# CTRL_MODULE_CORE register map
Vendor: Texas Instruments
Registers are 32-bit, access per field, reset 0x0 unless marked. A register's access mark holds for its fields unless they carry their own. Offsets are as the file gives them; [hi:lo] are bit positions; {n}, {i} and the like mark numbered series.

## CTRL_MODULE_CORE (part 2 of 12)
0x134 CTRL_CORE_STATUS ro reset 0xC0 — Control Module Status Register
  [8:6] DEVICE_TYPE — Device type captured at reset time. Read 0x3 = General Purpose (GP)
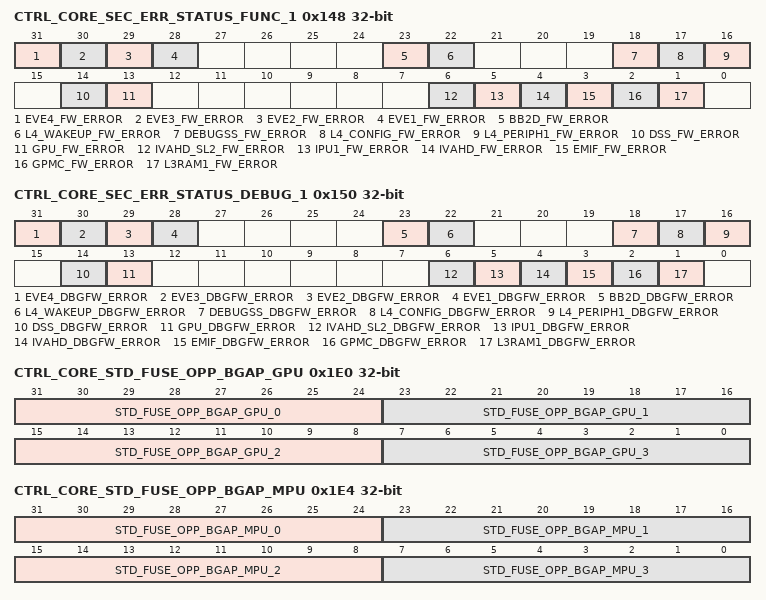
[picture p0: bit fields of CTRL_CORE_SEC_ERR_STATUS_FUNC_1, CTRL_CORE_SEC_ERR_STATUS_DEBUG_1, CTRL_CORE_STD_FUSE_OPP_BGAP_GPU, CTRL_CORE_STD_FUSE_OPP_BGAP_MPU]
0x148 CTRL_CORE_SEC_ERR_STATUS_FUNC_1 access not given — Firewall Error Status functional Register 1
  [31] EVE4_FW_ERROR — EVE4 firewall 0x0: No error firewall 0x1: Error from firewall (access RW W1toClr)
  [30] EVE3_FW_ERROR — EVE3 firewall 0x0: No error firewall 0x1: Error from firewall (access RW W1toClr)
  [29] EVE2_FW_ERROR — EVE2 firewall 0x0 = No error from firewall 0x1 = Error from firewall (access RW W1toClr)
  [28] EVE1_FW_ERROR — EVE1 firewall 0x0 = No error from firewall 0x1 = Error from firewall (access RW W1toClr)
  [23] BB2D_FW_ERROR — BB2D firewall 0x0 = No error from firewall 0x1 = Error from firewall (access RW W1toClr)
  [22] L4_WAKEUP_FW_ERROR — L4 wakeup firewall 0x0 = No error from firewall 0x1 = Error from firewall (access RW W1toClr)
  [18] DEBUGSS_FW_ERROR — DebugSS firewall 0x0 = No error from firewall 0x1 = Error from firewall (access RW W1toClr)
  [17] L4_CONFIG_FW_ERROR — L4 config firewall 0x0 = No error from firewall 0x1 = Error from firewall (access RW W1toClr)
  [16] L4_PERIPH1_FW_ERROR — L4 periph1 firewall 0x0 = No error from firewall 0x1 = Error from firewall (access RW W1toClr)
  [14] DSS_FW_ERROR — DSS firewall 0x0 = No error from firewall 0x1 = Error from firewall (access RW W1toClr)
  [13] GPU_FW_ERROR — GPU firewall 0x0 = No error from firewall 0x1 = Error from firewall (access RW W1toClr)
  [6] IVAHD_SL2_FW_ERROR — IVAHD SL2 firewall 0x0 = No error from firewall 0x1 = Error from firewall (access RW W1toClr)
  [5] IPU1_FW_ERROR — IPU1 firewall 0x0 = No error from firewall 0x1 = Error from firewall (access RW W1toClr)
  [4] IVAHD_FW_ERROR — IVAHD firewall 0x0 = No error from firewall 0x1 = Error from firewall (access RW W1toClr)
  [3] EMIF_FW_ERROR — EMIF firewall 0x0 = No error from firewall 0x1 = Error from firewall (access RW W1toClr)
  [2] GPMC_FW_ERROR — GPMC firewall 0x0 = No error from firewall 0x1 = Error from firewall (access RW W1toClr)
  [1] L3RAM1_FW_ERROR — L3RAM1 firewall 0x0 = No error from firewall 0x1 = Error from firewall (access RW W1toClr)
0x150 CTRL_CORE_SEC_ERR_STATUS_DEBUG_1 access not given — Firewall Error Status Debug Register 1
  [31] EVE4_DBGFW_ERROR — EVE4 firewall 0x0: No error firewall 0x1: Error from firewall (access RW W1toClr)
  [30] EVE3_DBGFW_ERROR — EVE3 firewall 0x0: No error firewall 0x1: Error from firewall (access RW W1toClr)
  [29] EVE2_DBGFW_ERROR — EVE2 firewall 0x0 = No error from firewall 0x1 = Error from firewall (access RW W1toClr)
  [28] EVE1_DBGFW_ERROR — EVE1 firewall 0x0 = No error from firewall 0x1 = Error from firewall (access RW W1toClr)
  [23] BB2D_DBGFW_ERROR — BB2D firewall 0x0 = No error from firewall 0x1 = Error from firewall (access RW W1toClr)
  [22] L4_WAKEUP_DBGFW_ERROR — L4 wakeup firewall 0x0 = No error from firewall 0x1 = Error from firewall (access RW W1toClr)
  [18] DEBUGSS_DBGFW_ERROR — DebugSS firewall 0x0 = No error from firewall 0x1 = Error from firewall (access RW W1toClr)
  [17] L4_CONFIG_DBGFW_ERROR — L4 config firewall 0x0 = No error from firewall 0x1 = Error from firewall (access RW W1toClr)
  [16] L4_PERIPH1_DBGFW_ERROR — L4 periph1 firewall 0x0 = No error from firewall 0x1 = Error from firewall (access RW W1toClr)
  [14] DSS_DBGFW_ERROR — DSS debug firewall 0x0 = No error from firewall 0x1 = Error from firewall (access RW W1toClr)
  [13] GPU_DBGFW_ERROR — GPU debug firewall 0x0 = No error from firewall 0x1 = Error from firewall (access RW W1toClr)
  [6] IVAHD_SL2_DBGFW_ERROR — IVAHD SL2 debug firewall 0x0 = No error from firewall 0x1 = Error from firewall (access RW W1toClr)
  [5] IPU1_DBGFW_ERROR — IPU1 debug firewall 0x0 = No error from firewall 0x1 = Error from firewall (access RW W1toClr)
  [4] IVAHD_DBGFW_ERROR — IVAHD debug firewall 0x0 = No error from firewall 0x1 = Error from firewall (access RW W1toClr)
  [3] EMIF_DBGFW_ERROR — EMIF debug firewall 0x0 = No error from firewall 0x1 = Error from firewall (access RW W1toClr)
  [2] GPMC_DBGFW_ERROR — GPMC debug firewall 0x0 = No error from firewall 0x1 = Error from firewall (access RW W1toClr)
  [1] L3RAM1_DBGFW_ERROR — L3RAM1 debug firewall 0x0 = No error from firewall 0x1 = Error from firewall (access RW W1toClr)
0x15C CTRL_CORE_MPU_FORCEWRNP — FORCE WRITE NON POSTED
  [0] MPU_FORCEWRNP rw — Force mpu write non posted transactions 0x0 = disable force wrnp 0x1 = force wrnp
{0x194+4i} CTRL_CORE_STD_FUSE_OPP_VDD_GPU_{i} ro (i=0..5) — Standard Fuse OPP VDD_GPU [{32i+31}:{32i}]. Register shows part of the chip eFuse configuration on the OCP interface. Reading at the address of one of these registers provides a direct view into a part of the eFuse chain.
  [31:0] STD_FUSE_OPP_VDD_GPU_{i}
{0x1AC+4i} CTRL_CORE_STD_FUSE_OPP_VDD_MPU_{i} ro (i=0..7) — Standard Fuse OPP VDD_MPU [{32i+31}:{32i}]. Register shows part of the chip eFuse configuration on the OCP interface. Reading at the address of one of these registers provides a direct view into a part of the eFuse chain.
  [31:0] STD_FUSE_OPP_VDD_MPU_{i}
{0x1CC+4i} CTRL_CORE_STD_FUSE_OPP_VDD_CORE_{i} ro (i=0..4) — Standard Fuse OPP VDD_CORE [{32i+31}:{32i}]. Register shows part of the chip eFuse configuration on the OCP interface. Reading at the address of one of these registers provides a direct view into a part of the eFuse chain.
  [31:0] STD_FUSE_OPP_VDD_CORE_{i}
0x1E0 CTRL_CORE_STD_FUSE_OPP_BGAP_GPU ro reset not defined — Trim values for GPU associated temperature sensor and bandgap. Contains TI Internal information, not intended for application use.
  [31-8n:24-8n] STD_FUSE_OPP_BGAP_GPU_{n} (n=0..3) — Trim values for GPU associated temperature sensor and bandgap. Contains TI Internal information, not intended for application use.
0x1E4 CTRL_CORE_STD_FUSE_OPP_BGAP_MPU ro reset not defined — Trim values for MPU associated temperature sensor and bandgap. Contains TI Internal information, not intended for application use.
  [31-8n:24-8n] STD_FUSE_OPP_BGAP_MPU_{n} (n=0..3) — Trim values for MPU associated temperature sensor and bandgap. Contains TI Internal information, not intended for application use.
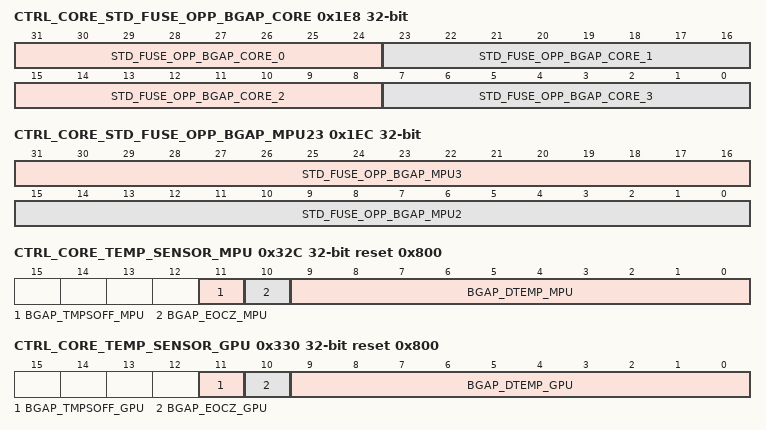
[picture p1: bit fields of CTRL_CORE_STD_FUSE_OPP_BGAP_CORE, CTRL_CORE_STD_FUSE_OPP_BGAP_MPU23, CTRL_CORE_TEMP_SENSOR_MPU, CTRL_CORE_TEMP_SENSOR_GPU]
0x1E8 CTRL_CORE_STD_FUSE_OPP_BGAP_CORE ro reset not defined — Trim values for CORE associated temperature sensor and bandgap. Contains TI Internal information, not intended for application use.
  [31-8n:24-8n] STD_FUSE_OPP_BGAP_CORE_{n} (n=0..3) — Trim values for CORE associated temperature sensor and bandgap. Contains TI Internal information, not intended for application use.
0x1EC CTRL_CORE_STD_FUSE_OPP_BGAP_MPU23 ro — Standard Fuse OPP BGAP. Register shows part of the chip eFuse configuration on the OCP interface. Reading at the address of one of these registers provides a direct view into a part of the eFuse chain.
  [31:16] STD_FUSE_OPP_BGAP_MPU3, [15:0] STD_FUSE_OPP_BGAP_MPU2
{0x220+4i} CTRL_CORE_STD_FUSE_MPK_{i} ro (i=0..7) — Standard Fuse keys. Root_public_key_hash [{32i+31}:{32i}]. Register shows part of the chip eFuse configuration on the OCP interface. Reading at the address of one of these registers provides a direct view into a part of the eFuse chain.
  [31:0] STD_FUSE_MPK_{i}
{0x240+4i} CTRL_CORE_STD_FUSE_OPP_VDD_GPU_LVT_{i} ro (i=0..5) — Standard Fuse OPP VDD_GPU [{32i+31}:{32i}]. Register shows part of the chip eFuse configuration on the OCP interface. Reading at the address of one of these registers provides a direct view into a part of the eFuse chain.
  [31:0] STD_FUSE_OPP_VDD_GPU_LVT_{i}
{0x258+4i} CTRL_CORE_STD_FUSE_OPP_VDD_MPU_LVT_{i} ro (i=0..7) — Standard Fuse OPP VDD_MPU [{32i+31}:{32i}]. Register shows part of the chip eFuse configuration on the OCP interface. Reading at the address of one of these registers provides a direct view into a part of the eFuse chain.
  [31:0] STD_FUSE_OPP_VDD_MPU_LVT_{i}
0x2BC CTRL_CORE_CUST_FUSE_SWRV_0 ro — Customer Fuse keys. Software Version Control [031:000] (16 bits upper Redundant field) [FIELD OVERFLOW]. Register shows part of the chip eFuse configuration on the OCP interface. Reading at the address of one of these registers provides a direct view into a part of the eFuse chain.
  [31:0] CUST_FUSE_SWRV_0
0x2C0 CTRL_CORE_CUST_FUSE_SWRV_1 ro — Customer Fuse keys. Software Version Control [063:032] (16 bits upper Redundant field) [FIELD F]. Register shows part of the chip eFuse configuration on the OCP interface. Reading at the address of one of these registers provides a direct view into a part of the eFuse chain.
  [31:0] CUST_FUSE_SWRV_1
0x2C4 CTRL_CORE_CUST_FUSE_SWRV_2 ro — Customer Fuse keys. Software Version Control [095:064] (16 bits upper Redundant field) [FIELD E]. Register shows part of the chip eFuse configuration on the OCP interface. Reading at the address of one of these registers provides a direct view into a part of the eFuse chain.
  [31:0] CUST_FUSE_SWRV_2
0x2C8 CTRL_CORE_CUST_FUSE_SWRV_3 ro — Customer Fuse keys. Software Version Control [127:096] (16 bits upper Redundant field) [FIELD D]. Register shows part of the chip eFuse configuration on the OCP interface. Reading at the address of one of these registers provides a direct view into a part of the eFuse chain.
  [31:0] CUST_FUSE_SWRV_3
0x2CC CTRL_CORE_CUST_FUSE_SWRV_4 ro — Customer Fuse keys. Software Version Control [159:127] (16 bits upper Redundant field) [FIELD C]. Register shows part of the chip eFuse configuration on the OCP interface. Reading at the address of one of these registers provides a direct view into a part of the eFuse chain.
  [31:0] CUST_FUSE_SWRV_4
0x2D0 CTRL_CORE_CUST_FUSE_SWRV_5 ro — Customer Fuse keys. Software Version Control [191:160] (16 bits upper Redundant field) [FIELD B]. Register shows part of the chip eFuse configuration on the OCP interface. Reading at the address of one of these registers provides a direct view into a part of the eFuse chain.
  [31:0] CUST_FUSE_SWRV_5
0x2D4 CTRL_CORE_CUST_FUSE_SWRV_6 ro — Customer Fuse keys. Software Version Control [223:192] (16 bits upper Redundant field) [FIELD A]. Register shows part of the chip eFuse configuration on the OCP interface. Reading at the address of one of these registers provides a direct view into a part of the eFuse chain.
  [31:0] CUST_FUSE_SWRV_6
0x300 CTRL_CORE_DEV_CONF ro — This register is used to power down the USB2_PHY1
  [0] USBPHY_PD — Power down the entire USB2_PHY1 (data, common module and UTMI). 0x0: Normal operation 0x1: Power down the USB2_PHY1
0x32C CTRL_CORE_TEMP_SENSOR_MPU ro reset 0x800 — Control VBGAPTS temperature sensor and thermal comparator shutdown register
  [11] BGAP_TMPSOFF_MPU — This bit indicates the temperature sensor state.
  [10] BGAP_EOCZ_MPU — ADC End of Conversion. Active low, when BGAP_DTEMP_MPU is valid.
  [9:0] BGAP_DTEMP_MPU — Temperature data from the ADC. Valid if EOCZ is low.
0x330 CTRL_CORE_TEMP_SENSOR_GPU ro reset 0x800 — Control VBGAPTS temperature sensor and thermal comparator shutdown register
  [11] BGAP_TMPSOFF_GPU — This bit indicates the temperature sensor state.
  [10] BGAP_EOCZ_GPU — ADC End of Conversion. Active low, when BGAP_DTEMP_GPU is valid.
  [9:0] BGAP_DTEMP_GPU — Temperature data from the ADC. Valid if EOCZ is low.
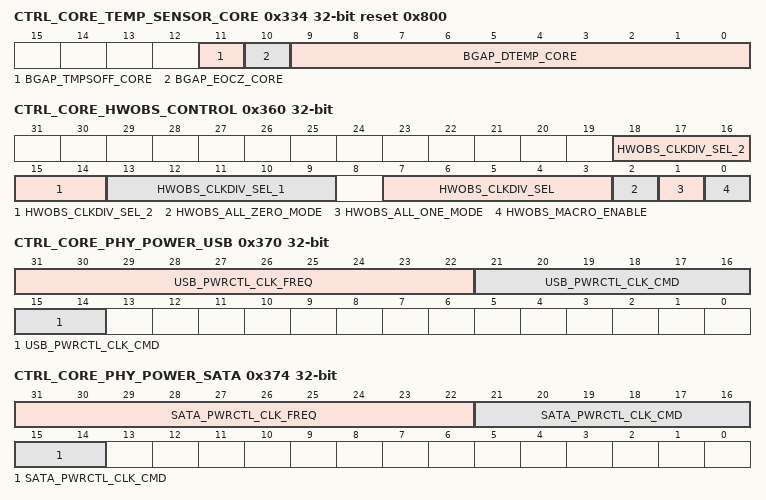
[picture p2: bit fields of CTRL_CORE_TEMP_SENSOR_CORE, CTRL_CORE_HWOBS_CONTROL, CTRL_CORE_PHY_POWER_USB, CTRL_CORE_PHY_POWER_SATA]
0x334 CTRL_CORE_TEMP_SENSOR_CORE ro reset 0x800 — Control VBGAPTS temperature sensor and thermal comparator shutdown register
  [11] BGAP_TMPSOFF_CORE — This bit indicates the temperature sensor state.
  [10] BGAP_EOCZ_CORE — ADC End of Conversion. Active low, when BGAP_DTEMP_CORE is valid.
  [9:0] BGAP_DTEMP_CORE — Temperature data from the ADC. Valid if EOCZ is low.
0x358 CTRL_CORE_CORTEX_M4_MMUADDRTRANSLTR — Cortex M4 register
  [19:0] CORTEX_M4_MMUADDRTRANSLTR rw — Used to save the mmu address boot
0x35C CTRL_CORE_CORTEX_M4_MMUADDRLOGICTR
  [19:0] CORTEX_M4_MMUADDRLOGICTR rw
0x360 CTRL_CORE_HWOBS_CONTROL — HW observability control. This register enables or disables HW observability outputs (to save power primarily)
  [18:14] HWOBS_CLKDIV_SEL_2 rw — Clock divider selection on po_hwobs(2). 0x1 = output is not divided 0x2 = output is divided by 2 0x4 = output is divided by 4 0x8 = output is divided by 8 0x10 = output is divided by 16
  [13:9] HWOBS_CLKDIV_SEL_1 rw — Clock divider selection on po_hwobs(1). 0x1 = output is not divided 0x2 = output is divided by 2 0x4 = output is divided by 4 0x8 = output is divided by 8 0x10 = output is divided by 16
  [7:3] HWOBS_CLKDIV_SEL rw — Clock divider selection on po_hwobs(0). 0x1 = output is not divided 0x2 = output is divided by 2 0x4 = output is divided by 4 0x8 = output is divided by 8 0x10 = output is divided by 16
  [2] HWOBS_ALL_ZERO_MODE rw — Used to gate observable signals. When set all outputs are set to zero (can be used to check the path from HW observability to external pads). 0x0 = hw observability ports are not gated 0x1 = hw observability ports are all set to 0
  [1] HWOBS_ALL_ONE_MODE rw — Used to gate observable signals. When set all outputs are set to one (can be used to check the path from HW observability to external pads). 0x0 = hw observability ports are not gated 0x1 = hw observability ports are all set to 1
  [0] HWOBS_MACRO_ENABLE rw — Used to gate observable signals coming from macros using the 32:bit HWOBS bus definition. When deasserted all outputs of the HWOBS busdef are set to zero. 0x0 = hw observability ports from macros are gated and set to zero 0x1 = hw observability ports from macros are not gated
0x370 CTRL_CORE_PHY_POWER_USB — phy_power_usb
  [31:22] USB_PWRCTL_CLK_FREQ rw — Frequency of SYSCLK1 in MHz (rounded). For example, for 20MHz, program 0x14.
  [21:14] USB_PWRCTL_CLK_CMD rw — Powers up/down the USB3_PHY_TX and USB3_PHY_RX modules. This bit field is also used for partially power down these TX and RX modules. Each bit has the following meaning: Bit[14] - 0x1: Powers-up the USB3_PHY_RX Bit[15] - 0x1: Powers-up the USB3_PHY_TX Bit[16] - A don’t care bit. Not used. Bit[17] - A don’t care bit. Not used. Bit[18] - 0x1: Disables the synchronized power-up of USB3_PHY_TX with USB3_PHY_RX. The TX power-up is independent of the RX power-up. Bit[19] - 0x1: Disables the automatic power-cycling of USB3_PHY_RX in P3 power state when PLL_CLK stops and starts. Bit[20] - 0x1: Partially powers-down the USB3_PHY_RX when it is in P3 power state. DCC, Phase interpolator, Equalizer are disabled. Bit[21] - A don’t care bit. Not used.
0x374 CTRL_CORE_PHY_POWER_SATA — phy_power_sata
  [31:22] SATA_PWRCTL_CLK_FREQ rw — Frequency of SYSCLK1 in MHz (rounded). For example, for 20MHz, program 0x14.
  [21:14] SATA_PWRCTL_CLK_CMD rw — Powers up/down the SATA_PHY_TX and SATA_PHY_RX modules. 0x0: Powers down SATA_PHY_TX and SATA_PHY_RX 0x1: Powers up SATA_PHY_RX 0x2: Powers up SATA_PHY_TX 0x3: Powers up SATA_PHY_TX and SATA_PHY_RX 0x4-0xFF: Reserved
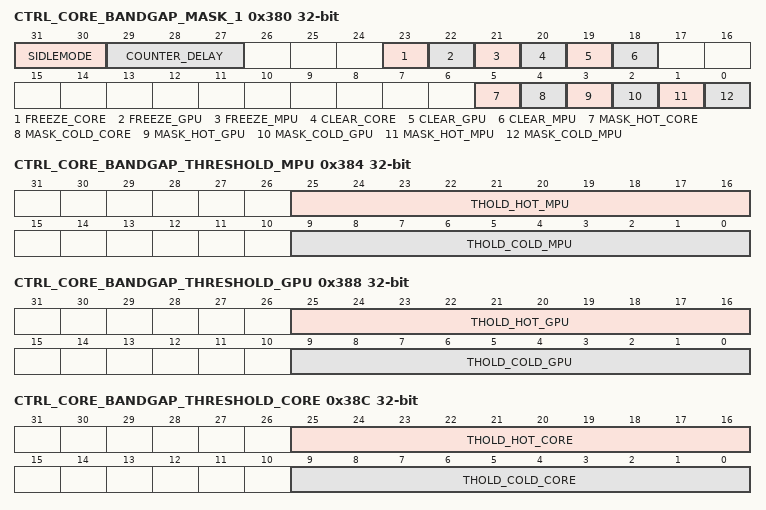
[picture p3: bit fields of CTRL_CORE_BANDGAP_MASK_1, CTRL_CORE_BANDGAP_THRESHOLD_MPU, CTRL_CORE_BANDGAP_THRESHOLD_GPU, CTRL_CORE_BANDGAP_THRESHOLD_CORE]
0x380 CTRL_CORE_BANDGAP_MASK_1 — bgap_mask
  [31:30] SIDLEMODE rw — sidlemode for bandgap 0x0 = No Idle 0x1 = Force Idle 0x2 = Smart Idle 0x3 = Reserved
  [29:27] COUNTER_DELAY rw — Counter delay 0x0 = Imediat 0x1 = Delay of 1ms 0x2 = Delay of 10ms 0x3 = Delay of 100ms 0x4 = Delay of 250ms 0x5 = Delay of 500ms
  [23] FREEZE_CORE rw — Freeze the FIFO CORE 0x0 = No operation 0x1 = Freeze the FIFO
  [22] FREEZE_GPU rw — Freeze the FIFO GPU 0x0 = No operation 0x1 = Freeze the FIFO
  [21] FREEZE_MPU rw — Freeze the FIFO MPU 0x0 = No operation 0x1 = Freeze the FIFO
  [20] CLEAR_CORE rw — Reset the FIFO CORE 0x0 = No operation 0x1 = Reset the FIFO
  [19] CLEAR_GPU rw — Reset the FIFO GPU 0x0 = No operation 0x1 = Reset the FIFO
  [18] CLEAR_MPU rw — Reset the FIFO MPU 0x0 = No operation 0x1 = Reset the FIFO
  [5] MASK_HOT_CORE rw — Mask for hot event CORE 0x0 = hot event is masked 0x1 = hot event is not masked
  [4] MASK_COLD_CORE rw — Mask for cold event CORE 0x0 = cold event is masked 0x1 = cold event is not masked
  [3] MASK_HOT_GPU rw — Mask for hot event GPU 0x0 = hot event is masked 0x1 = hot event is not masked
  [2] MASK_COLD_GPU rw — Mask for cold event GPU 0x0 = cold event is masked 0x1 = cold event is not masked
  [1] MASK_HOT_MPU rw — Mask for hot event MPU 0x0 = hot event is masked 0x1 = hot event is not masked
  [0] MASK_COLD_MPU rw — Mask for cold event MPU 0x0 = cold event is masked 0x1 = cold event is not masked
0x384 CTRL_CORE_BANDGAP_THRESHOLD_MPU — BGAP THRESHOLD MPU
  [25:16] THOLD_HOT_MPU rw — Value for the high temperature threshold. The values for loading this bit field are listed in.
  [9:0] THOLD_COLD_MPU rw — Value for the low temperature threshold. The values for loading this bit field are listed in.
0x388 CTRL_CORE_BANDGAP_THRESHOLD_GPU — BGAP THRESHOLD MM
  [25:16] THOLD_HOT_GPU rw — Value for the high temperature threshold. The values for loading this bit field are listed in.
  [9:0] THOLD_COLD_GPU rw — Value for the low temperature threshold. The values for loading this bit field are listed in.
0x38C CTRL_CORE_BANDGAP_THRESHOLD_CORE — BGAP THRESHOLD CORE
  [25:16] THOLD_HOT_CORE rw — Value for the high temperature threshold. The values for loading this bit field are listed in.
  [9:0] THOLD_COLD_CORE rw — Value for the low temperature threshold. The values for loading this bit field are listed in.
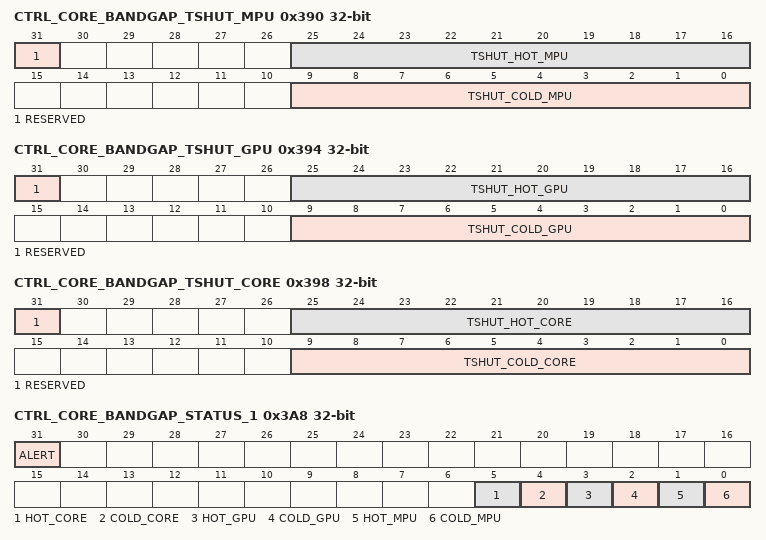
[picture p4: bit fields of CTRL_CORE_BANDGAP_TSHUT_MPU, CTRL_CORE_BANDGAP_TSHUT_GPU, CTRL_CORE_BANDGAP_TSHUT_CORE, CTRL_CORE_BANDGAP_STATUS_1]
0x390 CTRL_CORE_BANDGAP_TSHUT_MPU — BGAP TSHUT THRESHOLD MPU
  [31] RESERVED rw — Software should not modify this bit.
  [25:16] TSHUT_HOT_MPU rw — tshut value hot Software should not modify this bit field.
  [9:0] TSHUT_COLD_MPU rw — tshut value cold Software should not modify this bit field.
0x394 CTRL_CORE_BANDGAP_TSHUT_GPU — BGAP TSHUT THRESHOLD GPU
  [31] RESERVED rw — Software should not modify this bit.
  [25:16] TSHUT_HOT_GPU rw — tshut value hot Software should not modify this bit field.
  [9:0] TSHUT_COLD_GPU rw — tshut value cold Software should not modify this bit field.
0x398 CTRL_CORE_BANDGAP_TSHUT_CORE — BGAP TSHUT THRESHOLD CORE
  [31] RESERVED rw — Software should not modify this bit.
  [25:16] TSHUT_HOT_CORE rw — tshut value hot Software should not modify this bit field.
  [9:0] TSHUT_COLD_CORE rw — tshut value cold Software should not modify this bit field.
0x3A8 CTRL_CORE_BANDGAP_STATUS_1 ro — BGAP STATUS
  [31] ALERT — Alert temperature when '1'
  [5] HOT_CORE — Event for hot temperature mpu bandgap when '1' 0x0 = event not detected 0x1 = event detected
  [4] COLD_CORE — Event for cold temperature mpu bandgap when '1' 0x0 = event not detected 0x1 = event detected
  [3] HOT_GPU — Event for hot temperature gpu bandgap when '1' 0x0 = event not detected 0x1 = event detected
  [2] COLD_GPU — Event for cold temperature gpu bandgap when '1' 0x0 = event not detected 0x1 = event detected
  [1] HOT_MPU — Event for hot temperature core bandgap when '1' 0x0 = event not detected 0x1 = event detected
  [0] COLD_MPU — Event for cold temperature core bandgap when '1' 0x0 = event not detected 0x1 = event detected
0x3AC CTRL_CORE_SATA_EXT_MODE — SATA EXTENDED MODE
  [0] SATA_EXTENDED_MODE rw — sata extended mode 0x0 = no extended mode 0x1 = extended mode
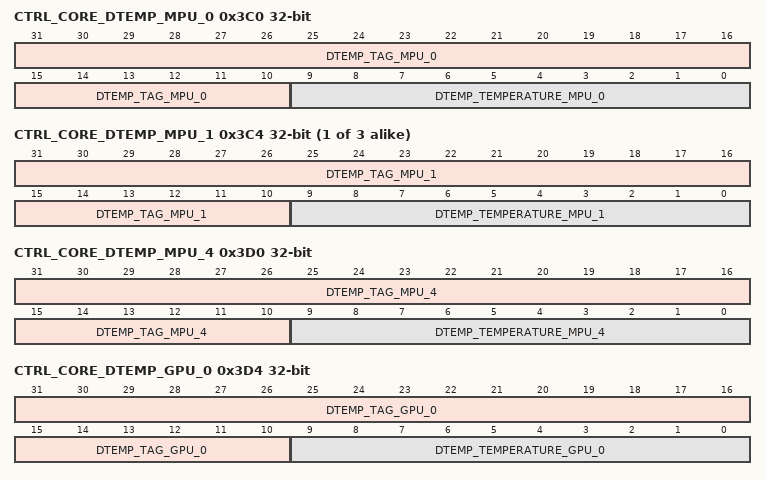
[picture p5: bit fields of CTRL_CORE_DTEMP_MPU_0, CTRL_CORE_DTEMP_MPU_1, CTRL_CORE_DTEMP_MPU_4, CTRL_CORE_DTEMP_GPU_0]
0x3C0 CTRL_CORE_DTEMP_MPU_0 ro — TAGGED TEMPERATURE MPU DOMAIN. Most recent sample
  [31:10] DTEMP_TAG_MPU_0 — tag. Indicate number of times in the bgap state machine.
  [9:0] DTEMP_TEMPERATURE_MPU_0 — temperature
{0x3C0+4i} CTRL_CORE_DTEMP_MPU_{i} ro (i=1..3) — TAGGED TEMPERATURE MPU DOMAIN
  [31:10] DTEMP_TAG_MPU_{i} — tag. Indicate number of times in the bgap state machine.
  [9:0] DTEMP_TEMPERATURE_MPU_{i} — temperature
0x3D0 CTRL_CORE_DTEMP_MPU_4 ro — TAGGED TEMPERATURE MPU DOMAIN. Oldest sample
  [31:10] DTEMP_TAG_MPU_4 — tag. Indicate number of times in the bgap state machine.
  [9:0] DTEMP_TEMPERATURE_MPU_4 — temperature
0x3D4 CTRL_CORE_DTEMP_GPU_0 ro — TAGGED TEMPERATURE GPU DOMAIN. Most recent sample.
  [31:10] DTEMP_TAG_GPU_0 — tag. Indicate number of times in the bgap state machine.
  [9:0] DTEMP_TEMPERATURE_GPU_0 — temperature
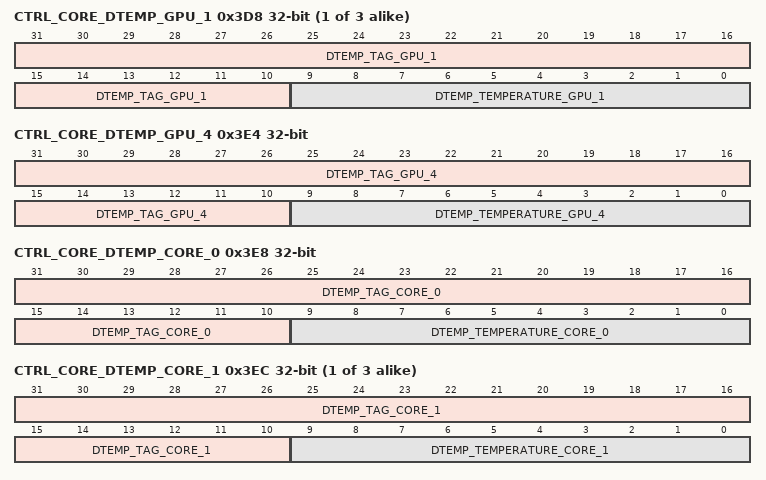
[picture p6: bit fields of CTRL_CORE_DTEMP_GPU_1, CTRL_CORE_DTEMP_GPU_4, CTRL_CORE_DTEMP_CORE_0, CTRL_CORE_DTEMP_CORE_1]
{0x3D4+4i} CTRL_CORE_DTEMP_GPU_{i} ro (i=1..3) — TAGGED TEMPERATURE GPU DOMAIN.
  [31:10] DTEMP_TAG_GPU_{i} — tag. Indicate number of times in the bgap state machine.
  [9:0] DTEMP_TEMPERATURE_GPU_{i} — temperature
0x3E4 CTRL_CORE_DTEMP_GPU_4 ro — TAGGED TEMPERATURE GPU DOMAIN. Oldest sample.
  [31:10] DTEMP_TAG_GPU_4 — tag. Indicate number of times in the bgap state machine.
  [9:0] DTEMP_TEMPERATURE_GPU_4 — temperature
0x3E8 CTRL_CORE_DTEMP_CORE_0 ro — TAGGED TEMPERATURE CORE DOMAIN. Most recent sample.
  [31:10] DTEMP_TAG_CORE_0 — tag. Indicate number of times in the bgap state machine.
  [9:0] DTEMP_TEMPERATURE_CORE_0 — temperature
{0x3E8+4i} CTRL_CORE_DTEMP_CORE_{i} ro (i=1..3) — TAGGED TEMPERATURE CORE DOMAIN
  [31:10] DTEMP_TAG_CORE_{i} — tag. Indicate number of times in the bgap state machine.
  [9:0] DTEMP_TEMPERATURE_CORE_{i} — temperature
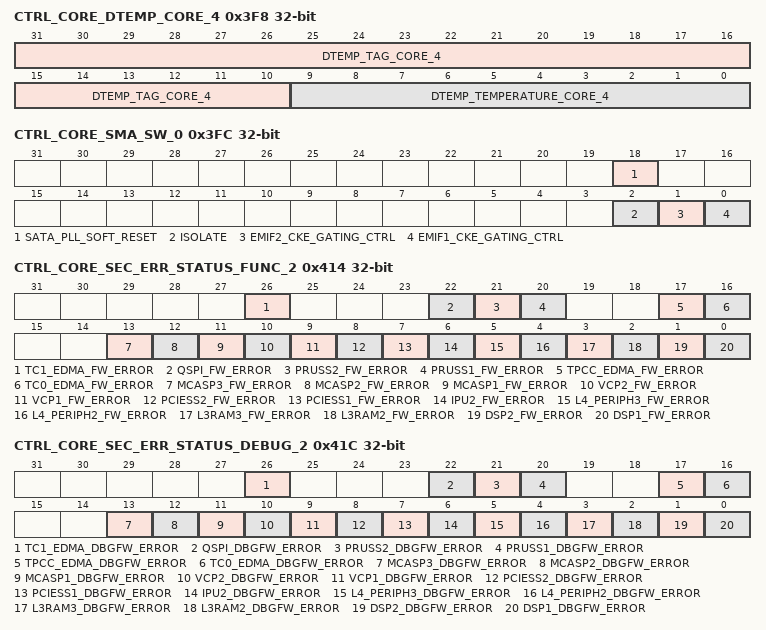
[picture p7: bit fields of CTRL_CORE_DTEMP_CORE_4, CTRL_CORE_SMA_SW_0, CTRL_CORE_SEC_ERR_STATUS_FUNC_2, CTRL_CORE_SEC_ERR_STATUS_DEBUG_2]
0x3F8 CTRL_CORE_DTEMP_CORE_4 ro — TAGGED TEMPERATURE CORE DOMAIN. Oldest sample.
  [31:10] DTEMP_TAG_CORE_4 — tag. Indicate number of times in the bgap state machine.
  [9:0] DTEMP_TEMPERATURE_CORE_4 — temperature
0x3FC CTRL_CORE_SMA_SW_0 — OCP Spare Register
  [18] SATA_PLL_SOFT_RESET rw — Software reset control for SATA PLL
  [2] ISOLATE rw — This bit is used during the isolation/de-isolation sequence described in, Isolation Requirements.
  [1] EMIF2_CKE_GATING_CTRL rw — Forces the EMIF2 CKE pad to tri-state. 0x0: The CKE pad is not in tri-state and can be controlled by EMIF2 0x1: The CKE pad is in tri-state
  [0] EMIF1_CKE_GATING_CTRL rw — Forces the EMIF1 CKE pad to tri-state. 0x0: The CKE pad is not in tri-state and can be controlled by EMIF1 0x1: The CKE pad is in tri-state
0x414 CTRL_CORE_SEC_ERR_STATUS_FUNC_2 access not given — Firewall Error Status functional Register 2
  [26] TC1_EDMA_FW_ERROR — EDMA TC1 firewall 0x0 = No error from firewall 0x1 = Error from firewall (access RW W1toClr)
  [22] QSPI_FW_ERROR — QSPI firewall 0x0 = No error from firewall 0x1 = Error from firewall (access RW W1toClr)
  [21] PRUSS2_FW_ERROR — PRU-ICSS2 firewall 0x0 = No error from firewall 0x1 = Error from firewall (access RW W1toClr)
  [20] PRUSS1_FW_ERROR — PRU-ICSS1 firewall 0x0 = No error from firewall 0x1 = Error from firewall (access RW W1toClr)
  [17] TPCC_EDMA_FW_ERROR — EDMA TPCC firewall 0x0 = No error from firewall 0x1 = Error from firewall (access RW W1toClr)
  [16] TC0_EDMA_FW_ERROR — EDMA TC0 firewall 0x0 = No error from firewall 0x1 = Error from firewall (access RW W1toClr)
  [13] MCASP3_FW_ERROR — McASP3 firewall 0x0 = No error from firewall 0x1 = Error from firewall (access RW W1toClr)
  [12] MCASP2_FW_ERROR — McASP2 firewall 0x0 = No error from firewall 0x1 = Error from firewall (access RW W1toClr)
  [11] MCASP1_FW_ERROR — McASP1 firewall 0x0 = No error from firewall 0x1 = Error from firewall (access RW W1toClr)
  [10] VCP2_FW_ERROR — VCP2 firewall 0x0 = No error from firewall 0x1 = Error from firewall (access RW W1toClr)
  [9] VCP1_FW_ERROR — VCP1 firewall 0x0 = No error from firewall 0x1 = Error from firewall (access RW W1toClr)
  [8] PCIESS2_FW_ERROR — PCIeSS2 firewall 0x0 = No error from firewall 0x1 = Error from firewall (access RW W1toClr)
  [7] PCIESS1_FW_ERROR — PCIeSS1 firewall 0x0 = No error from firewall 0x1 = Error from firewall (access RW W1toClr)
  [6] IPU2_FW_ERROR — IPU2 firewall. 0x0 = No error from firewall 0x1 = Error from firewall (access RW W1toClr)
  [5] L4_PERIPH3_FW_ERROR — L4 periph3 init firewall 0x0 = No error from firewall 0x1 = Error from firewall (access RW W1toClr)
  [4] L4_PERIPH2_FW_ERROR — L4 periph2 init firewall 0x0 = No error from firewall 0x1 = Error from firewall (access RW W1toClr)
  [3] L3RAM3_FW_ERROR — L3RAM3 firewall 0x0 = No error from firewall 0x1 = Error from firewall (access RW W1toClr)
  [2] L3RAM2_FW_ERROR — L3RAM2 target firewall. 0x0 = No error from firewall 0x1 = Error from firewall (access RW W1toClr)
  [1] DSP2_FW_ERROR — DSP2 firewall 0x0 = No error from firewall 0x1 = Error from firewall (access RW W1toClr)
  [0] DSP1_FW_ERROR — DSP1 firewall 0x0 = No error from firewall 0x1 = Error from firewall (access RW W1toClr)
0x41C CTRL_CORE_SEC_ERR_STATUS_DEBUG_2 access not given — Firewall Error Status debug Register 2
  [26] TC1_EDMA_DBGFW_ERROR — EDMA TC1 debug firewall 0x0 = No error from firewall 0x1 = Error from firewall (access RW W1toClr)
  [22] QSPI_DBGFW_ERROR — QSPI debug firewall 0x0 = No error from firewall 0x1 = Error from firewall (access RW W1toClr)
  [21] PRUSS2_DBGFW_ERROR — PRU-ICSS2 debug firewall 0x0 = No error from firewall 0x1 = Error from firewall (access RW W1toClr)
  [20] PRUSS1_DBGFW_ERROR — PRU-ICSS1 debug firewall 0x0 = No error from firewall 0x1 = Error from firewall (access RW W1toClr)
  [17] TPCC_EDMA_DBGFW_ERROR — EDMA TPCC debug firewall 0x0 = No error from firewall 0x1 = Error from firewall (access RW W1toClr)
  [16] TC0_EDMA_DBGFW_ERROR — EDMA TC0 debug firewall 0x0 = No error from firewall 0x1 = Error from firewall (access RW W1toClr)
  [13] MCASP3_DBGFW_ERROR — McASP3 debug firewall 0x0 = No error from firewall 0x1 = Error from firewall (access RW W1toClr)
  [12] MCASP2_DBGFW_ERROR — McASP2 debug firewall 0x0 = No error from firewall 0x1 = Error from firewall (access RW W1toClr)
  [11] MCASP1_DBGFW_ERROR — McASP1 debug firewall 0x0 = No error from firewall 0x1 = Error from firewall (access RW W1toClr)
  [10] VCP2_DBGFW_ERROR — VCP2 debug firewall 0x0 = No error from firewall 0x1 = Error from firewall (access RW W1toClr)
  [9] VCP1_DBGFW_ERROR — VCP1 debug firewall 0x0 = No error from firewall 0x1 = Error from firewall (access RW W1toClr)
  [8] PCIESS2_DBGFW_ERROR — PCIeSS2 debug firewall 0x0 = No error from firewall 0x1 = Error from firewall (access RW W1toClr)
  [7] PCIESS1_DBGFW_ERROR — PCIeSS1 debug firewall 0x0 = No error from firewall 0x1 = Error from firewall (access RW W1toClr)
  [6] IPU2_DBGFW_ERROR — IPU2 debug firewall 0x0 = No error from firewall 0x1 = Error from firewall (access RW W1toClr)
  [5] L4_PERIPH3_DBGFW_ERROR — L4 periph3 init firewall 0x0 = No error from firewall 0x1 = Error from firewall (access RW W1toClr)
  [4] L4_PERIPH2_DBGFW_ERROR — L4 periph2 init firewall 0x0 = No error from firewall 0x1 = Error from firewall (access RW W1toClr)
  [3] L3RAM3_DBGFW_ERROR — L3RAM3 firewall 0x0 = No error from firewall 0x1 = Error from firewall (access RW W1toClr)
  [2] L3RAM2_DBGFW_ERROR — L3RAM2 target debug firewall. 0x0 = No error from firewall 0x1 = Error from firewall (access RW W1toClr)
  [1] DSP2_DBGFW_ERROR — DSP2 firewall 0x0 = No error from firewall 0x1 = Error from firewall (access RW W1toClr)
  [0] DSP1_DBGFW_ERROR — DSP1 firewall 0x0 = No error from firewall 0x1 = Error from firewall (access RW W1toClr)
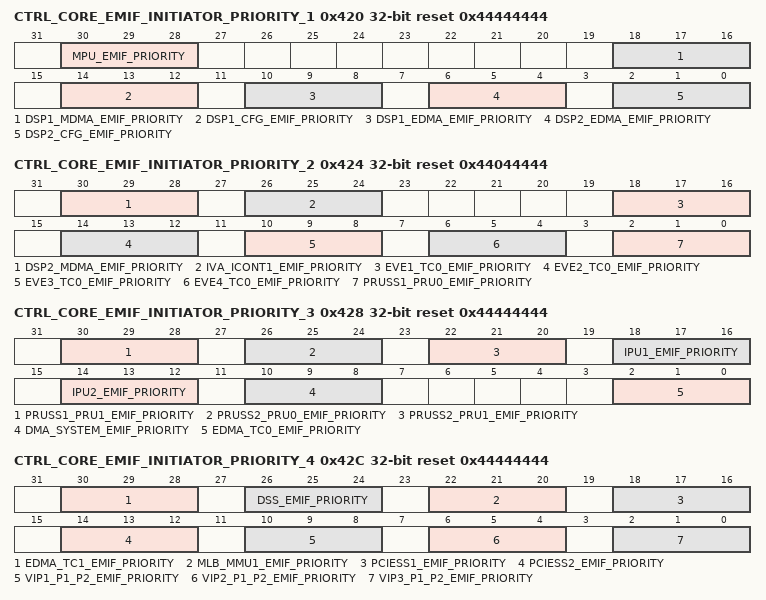
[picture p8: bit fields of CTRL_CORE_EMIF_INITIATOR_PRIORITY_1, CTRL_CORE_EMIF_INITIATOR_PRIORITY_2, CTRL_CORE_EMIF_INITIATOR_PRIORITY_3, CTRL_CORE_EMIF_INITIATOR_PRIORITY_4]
0x420 CTRL_CORE_EMIF_INITIATOR_PRIORITY_1 reset 0x44444444 — Register for priority settings for EMIF arbitration
  [30:28] MPU_EMIF_PRIORITY rw — MPU priority setting 0x0 = highest priority 0x7 = lowest priority
  [18:16] DSP1_MDMA_EMIF_PRIORITY rw — DSP1 MDMA priority setting 0x0 = highest priority 0x7 = lowest priority
  [14:12] DSP1_CFG_EMIF_PRIORITY rw — DSP1 CFG priority setting 0x0 = highest priority 0x7 = lowest priority
  [10:8] DSP1_EDMA_EMIF_PRIORITY rw — DSP1 EDMA priority setting 0x0 = highest priority 0x7 = lowest priority
  [6:4] DSP2_EDMA_EMIF_PRIORITY rw — DSP2 EDMA priority setting 0x0 = highest priority 0x7 = lowest priority
  [2:0] DSP2_CFG_EMIF_PRIORITY rw — DSP2 CFG priority setting 0x0 = highest priority 0x7 = lowest priority
0x424 CTRL_CORE_EMIF_INITIATOR_PRIORITY_2 reset 0x44044444 — Register for priority settings for EMIF arbitration
  [30:28] DSP2_MDMA_EMIF_PRIORITY rw — DSP2 MDMA priority setting 0x0 = highest priority 0x7 = lowest priority
  [26:24] IVA_ICONT1_EMIF_PRIORITY rw — IVA ICONT1 priority setting 0x0 = highest priority 0x7 = lowest priority
  [22-4n:20-4n] EVE{n}_TC0_EMIF_PRIORITY rw (n=1..4) — EVE{n} TC0 priority setting 0x0 = highest priority 0x7 = lowest priority
  [2:0] PRUSS1_PRU0_EMIF_PRIORITY rw — PRU-ICSS1 PRU0 priority setting 0x0 = highest priority 0x7 = lowest priority
0x428 CTRL_CORE_EMIF_INITIATOR_PRIORITY_3 reset 0x44444444 — Register for priority settings for EMIF arbitration
  [30:28] PRUSS1_PRU1_EMIF_PRIORITY rw — PRU-ICSS1 PRU1 priority setting 0x0 = highest prioroty 0x7 = lowest priority
  [26:24] PRUSS2_PRU0_EMIF_PRIORITY rw — PRU-ICSS2 PRU0 priority setting 0x0 = highest prioroty 0x7 = lowest priority
  [22:20] PRUSS2_PRU1_EMIF_PRIORITY rw — PRU-ICSS2 PRU1 priority setting 0x0 = highest prioroty 0x7 = lowest priority
  [18:16] IPU1_EMIF_PRIORITY rw — IPU1 priority setting 0x0 = highest prioroty 0x7 = lowest priority
  [14:12] IPU2_EMIF_PRIORITY rw — IPU2 priority setting 0x0 = highest priority 0x7 = lowest priority
  [10:8] DMA_SYSTEM_EMIF_PRIORITY rw — DMA SYSTEM priority setting 0x0 = highest priority 0x7 = lowest priority
  [2:0] EDMA_TC0_EMIF_PRIORITY rw — EDMA TC0 priority setting 0x0 = highest priority 0x7 = lowest priority
0x42C CTRL_CORE_EMIF_INITIATOR_PRIORITY_4 reset 0x44444444 — Register for priority settings for EMIF arbitration
  [30:28] EDMA_TC1_EMIF_PRIORITY rw — EDMA TC1 priority setting 0x0 = highest priority 0x7 = lowest priority
  [26:24] DSS_EMIF_PRIORITY rw — DSS priority setting 0x0 = highest priority 0x7 = lowest priority
  [22:20] MLB_MMU1_EMIF_PRIORITY rw — MLB, MMU1 priority setting 0x0 = highest priority 0x7 = lowest priority
  [18:16] PCIESS1_EMIF_PRIORITY rw — PCIeSS1 priority setting 0x0 = highest priority 0x7 = lowest priority
  [14:12] PCIESS2_EMIF_PRIORITY rw — PCIeSS2 priority setting 0x0 = highest priority 0x7 = lowest priority
  [10:8] VIP1_P1_P2_EMIF_PRIORITY rw — VIP1 priority setting 0x0 = highest priority 0x7 = lowest priority
  [6:4] VIP2_P1_P2_EMIF_PRIORITY rw — VIP2 priority setting 0x0 = highest priority 0x7 = lowest priority
  [2:0] VIP3_P1_P2_EMIF_PRIORITY rw — VIP3 priority setting 0x0 = highest priority 0x7 = lowest priority
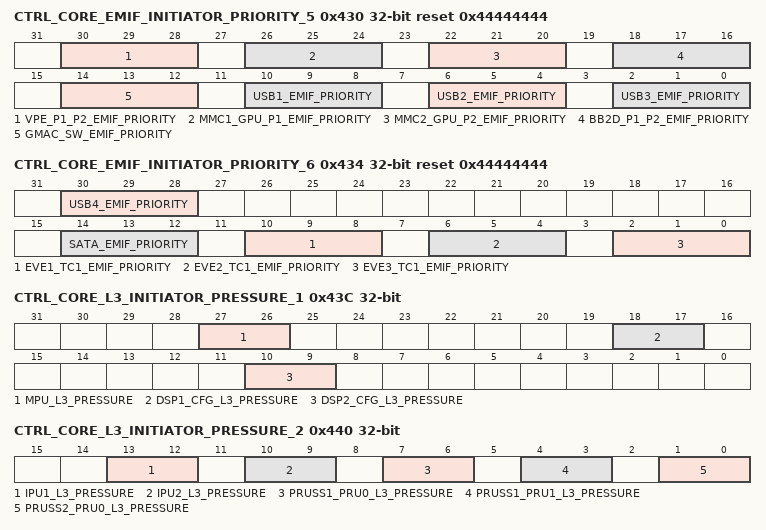
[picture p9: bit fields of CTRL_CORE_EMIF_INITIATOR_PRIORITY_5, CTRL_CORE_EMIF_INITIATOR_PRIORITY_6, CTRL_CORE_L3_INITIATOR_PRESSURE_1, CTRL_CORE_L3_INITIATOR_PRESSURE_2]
0x430 CTRL_CORE_EMIF_INITIATOR_PRIORITY_5 reset 0x44444444 — Register for priority settings for EMIF arbitration
  [30:28] VPE_P1_P2_EMIF_PRIORITY rw — VPE priority setting 0x0 = highest priority 0x7 = lowest priority
  [26:24] MMC1_GPU_P1_EMIF_PRIORITY rw — MMC1, GPU P1 priority setting 0x0 = highest priority 0x7 = lowest priority
  [22:20] MMC2_GPU_P2_EMIF_PRIORITY rw — MMC2, GPU P2 priority setting 0x0 = highest priority 0x7 = lowest priority
  [18:16] BB2D_P1_P2_EMIF_PRIORITY rw — BB2D priority setting 0x0 = highest priority 0x7 = lowest priority
  [14:12] GMAC_SW_EMIF_PRIORITY rw — GMAC_SW priority setting 0x0 = highest priority 0x7 = lowest priority
  [10:8] USB1_EMIF_PRIORITY rw — USB1 priority setting 0x0 = highest priority 0x7 = lowest priority
  [6:4] USB2_EMIF_PRIORITY rw — USB2 priority setting 0x0 = highest priority 0x7 = lowest priority
  [2:0] USB3_EMIF_PRIORITY rw — USB3 priority setting 0x0 = highest priority 0x7 = lowest priorty
0x434 CTRL_CORE_EMIF_INITIATOR_PRIORITY_6 reset 0x44444444 — Register for priority settings for EMIF arbitration
  [30:28] USB4_EMIF_PRIORITY rw — USB4 priority setting 0x0 = highest priority 0x7 = lowest prority
  [14:12] SATA_EMIF_PRIORITY rw — SATA priority setting 0x0 = highest priority 0x7 = lowest priority
  [10:8] EVE1_TC1_EMIF_PRIORITY rw — EVE1 TC1 priority setting 0x0 = highest priority 0x7 = lowest priority
  [6:4] EVE2_TC1_EMIF_PRIORITY rw — EVE2 TC1 priority setting 0x0 = highest priority 0x7 = lowest priority
  [2:0] EVE3_TC1_EMIF_PRIORITY rw — EVE3 TC1 priority setting 0x0 = highest priority 0x7 = lowest priority
0x438 CTRL_CORE_EMIF_INITIATOR_PRIORITY_7 reset 0x44444444 — Register for priority settings for EMIF arbitration
  [30:28] EVE4_TC1_EMIF_PRIORITY rw — EVE4 TC1 priority setting0x0 = highest priority enum=HIGHESTPRIORITY . 0x7 = lowest priority enum=LOWESTPRIORITY .
0x43C CTRL_CORE_L3_INITIATOR_PRESSURE_1 — Register for pressure settings for L3 arbitration
  [27:26] MPU_L3_PRESSURE rw — MPU pressure setting 0x0 = lowest 0x3 = highest
  [18:17] DSP1_CFG_L3_PRESSURE rw — DSP1 CFG pressure setting 0x0 = lowest 0x3 = highest
  [10:9] DSP2_CFG_L3_PRESSURE rw — DSP2 CFG pressure setting 0x0 = lowest 0x3 = highest
0x440 CTRL_CORE_L3_INITIATOR_PRESSURE_2 — Register for pressure settings for L3 arbitration
  [13:12] IPU1_L3_PRESSURE rw — IPU1 pressure setting 0x0 = lowest 0x3 = highest
  [10:9] IPU2_L3_PRESSURE rw — IPU2 pressure setting 0x0 = lowest 0x3 = highest
  [7:6] PRUSS1_PRU0_L3_PRESSURE rw — PRU-ICSS1 PRU0 pressure setting 0x0 = lowest 0x3 = highest
  [4:3] PRUSS1_PRU1_L3_PRESSURE rw — PRU-ICSS1 PRU1 pressure setting 0x0 = lowest 0x3 = highest
  [1:0] PRUSS2_PRU0_L3_PRESSURE rw — PRU-ICSS2 PRU0 pressure setting 0x0 = lowest 0x3 = highest
0x444 CTRL_CORE_L3_INITIATOR_PRESSURE_3 — Register for pressure settings for L3 arbitration
  [27:26] PRUSS2_PRU1_L3_PRESSURE rw — PRU-ICSS2 PRU1 pressure setting0x0 = lowest enum=LOWEST . 0x3 = highest enum=HIGHEST .
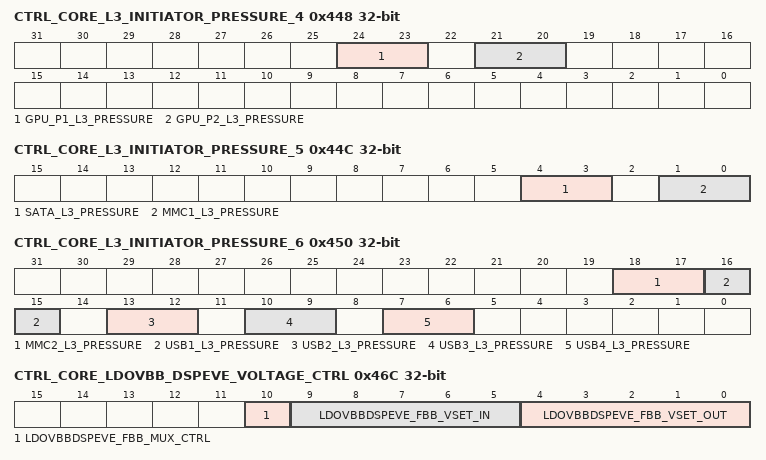
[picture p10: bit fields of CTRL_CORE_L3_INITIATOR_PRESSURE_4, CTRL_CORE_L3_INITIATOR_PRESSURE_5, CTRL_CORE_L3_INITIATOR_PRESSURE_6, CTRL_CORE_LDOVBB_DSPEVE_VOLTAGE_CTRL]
0x448 CTRL_CORE_L3_INITIATOR_PRESSURE_4 — Register for pressure settings for L3 arbitration
  [24:23] GPU_P1_L3_PRESSURE rw — GPU P1 pressure setting 0x0 = lowest 0x3 = highest
  [21:20] GPU_P2_L3_PRESSURE rw — GPU P2 pressure setting 0x0 = lowest 0x3 = highest
0x44C CTRL_CORE_L3_INITIATOR_PRESSURE_5 — Register for pressure settings for L3 arbitration
  [4:3] SATA_L3_PRESSURE rw — SATA pressure setting 0x0 = lowest 0x3 = highest
  [1:0] MMC1_L3_PRESSURE rw — MMC1 pressure setting 0x0 = lowest 0x3 = highest
0x450 CTRL_CORE_L3_INITIATOR_PRESSURE_6 — Register for pressure settings for L3 arbitration
  [18:17] MMC2_L3_PRESSURE rw — MMC2 pressure setting 0x0 = lowest 0x3 = highest
  [19-3n:18-3n] USB{n}_L3_PRESSURE rw (n=1..4) — USB{n} pressure setting 0x0 = lowest 0x3 = highest
{0x458+4i} CTRL_CORE_STD_FUSE_OPP_VDD_IVA_{i} ro (i=0..4) — Standard Fuse OPP VDD_iva [{32i+31}:{32i}]. Register shows part of the chip eFuse configuration on the OCP interface. Reading at the address of one of these registers provides a direct view into a part of the eFuse chain.
  [31:0] STD_FUSE_OPP_VDD_IVA_{i}
0x46C CTRL_CORE_LDOVBB_DSPEVE_VOLTAGE_CTRL — DSPEVE Voltage Body Bias LDO Control register
  [10] LDOVBBDSPEVE_FBB_MUX_CTRL rw — Override control of EFUSE Forward Body Bias voltage value 0x0 = efuse value is used 0x1 = override value is used
  [9:5] LDOVBBDSPEVE_FBB_VSET_IN ro — EFUSE Forward Body Bias voltage value
  [4:0] LDOVBBDSPEVE_FBB_VSET_OUT rw — Override value for Forward Body Bias voltage. If ABB is used, depending on the OPP this bit field should be loaded with a value read from one of the CTRL_CORE_STD_FUSE_OPP_VMIN_DSPEVE_x[24:20] VSETABB bit fields. This value applies if LDOVBBDSPEVE_FBB_MUX_CTRL is set to 0x1.
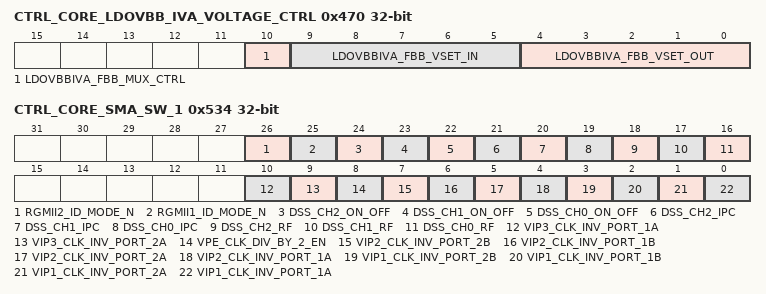
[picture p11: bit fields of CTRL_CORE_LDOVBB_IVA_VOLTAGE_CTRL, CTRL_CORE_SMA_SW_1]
0x470 CTRL_CORE_LDOVBB_IVA_VOLTAGE_CTRL — IVA Voltage Body Bias LDO Control register
  [10] LDOVBBIVA_FBB_MUX_CTRL rw — Override control of EFUSE Forward Body Bias voltage value 0x0 = efuse value is used 0x1 = override value is used
  [9:5] LDOVBBIVA_FBB_VSET_IN ro — EFUSE Forward Body Bias voltage value
  [4:0] LDOVBBIVA_FBB_VSET_OUT rw — Override value for Forward Body Bias voltage. If ABB is used, depending on the OPP this bit field should be loaded with a value read from one of the CTRL_CORE_STD_FUSE_OPP_VMIN_IVA_x[24:20] VSETABB bit fields. This value applies if LDOVBBIVA_FBB_MUX_CTRL is set to 0x1.
0x4E8 CTRL_CORE_CUST_FUSE_UID_0 ro — Customer Fuse keys. UID [031:000] (16 bits upper Redundant field) [FIELD OVERFLOW]. Register shows part of the chip eFuse configuration on the OCP interface. Reading at the address of one of these registers provides a direct view into a part of the eFuse chain.
  [31:0] CUST_FUSE_UID_0
0x4EC CTRL_CORE_CUST_FUSE_UID_1 ro — Customer Fuse keys. UID [063:032] (16 bits upper Redundant field) [FIELD F]. Register shows part of the chip eFuse configuration on the OCP interface. Reading at the address of one of these registers provides a direct view into a part of the eFuse chain.
  [31:0] CUST_FUSE_UID_1
0x4F0 CTRL_CORE_CUST_FUSE_UID_2 ro — Customer Fuse keys. UID [095:064] (16 bits upper Redundant field) [FIELD E]. Register shows part of the chip eFuse configuration on the OCP interface. Reading at the address of one of these registers provides a direct view into a part of the eFuse chain.
  [31:0] CUST_FUSE_UID_2
0x4F4 CTRL_CORE_CUST_FUSE_UID_3 ro — Customer Fuse keys. UID [127:096] (16 bits upper Redundant field) [FIELD D]. Register shows part of the chip eFuse configuration on the OCP interface. Reading at the address of one of these registers provides a direct view into a part of the eFuse chain.
  [31:0] CUST_FUSE_UID_3
0x4F8 CTRL_CORE_CUST_FUSE_UID_4 ro — Customer Fuse keys. UID [159:127] (16 bits upper Redundant field) [FIELD C]. Register shows part of the chip eFuse configuration on the OCP interface. Reading at the address of one of these registers provides a direct view into a part of the eFuse chain.
  [31:0] CUST_FUSE_UID_4
0x4FC CTRL_CORE_CUST_FUSE_UID_5 ro — Customer Fuse keys. UID [191:160] (16 bits upper Redundant field) [FIELD B]. Register shows part of the chip eFuse configuration on the OCP interface. Reading at the address of one of these registers provides a direct view into a part of the eFuse chain.
  [31:0] CUST_FUSE_UID_5
0x500 CTRL_CORE_CUST_FUSE_UID_6 ro — Customer Fuse keys. UID [223:192] (16 bits upper Redundant field) [FIELD A]. Register shows part of the chip eFuse configuration on the OCP interface. Reading at the address of one of these registers provides a direct view into a part of the eFuse chain.
  [31:0] CUST_FUSE_UID_6
0x508 CTRL_CORE_CUST_FUSE_PCIE_ID_0 ro — Customer Fuse keys. PCIe ID [031:000] (16 bits upper Redundant field) [FIELD OVERFLOW]. Register shows part of the chip eFuse configuration on the OCP interface. Reading at the address of one of these registers provides a direct view into a part of the eFuse chain.
  [31:0] CUST_FUSE_PCIE_ID_0
0x510 CTRL_CORE_CUST_FUSE_USB_ID_0 ro — Customer Fuse keys. USB ID [031:000] (16 bits upper Redundant field) [FIELD OVERFLOW]. Register shows part of the chip eFuse configuration on the OCP interface. Reading at the address of one of these registers provides a direct view into a part of the eFuse chain.
  [31:0] CUST_FUSE_USB_ID_0
0x514 CTRL_CORE_MAC_ID_SW_0 ro — Standard Fuse keys, MAC ID_1 [63:32].
  [24:0] STD_FUSE_MAC_ID_SW_0 — This bit field contains the last three octets (NIC specific) of the MAC address of the GMAC_SW port 0. Bits [23:16] contain the 4th octet of the MAC address. Bits [15:8] contain the 5th octet of the MAC address. Bits [7:0] contain the last (6th) octet of the MAC address.
0x518 CTRL_CORE_MAC_ID_SW_1 ro — Standard Fuse keys, MAC ID_1 [31:0].
  [24:0] STD_FUSE_MAC_ID_SW_1 — This bit field contains the first three octets (the OUI) of the MAC address of the GMAC_SW port 0. Bits [23:16] contain the first octet of the MAC address. Bits [15:8] contain the second octet of the MAC address. Bits [7:0] contain the third octet of the MAC address.
0x51C CTRL_CORE_MAC_ID_SW_2 ro — Standard Fuse keys, MAC ID_2 [63:32].
  [24:0] STD_FUSE_MAC_ID_SW_2 — This bit field contains the last three octets (NIC specific) of the MAC address of the GMAC_SW port 1. Bits [23:16] contain the 4th octet of the MAC address. Bits [15:8] contain the 5th octet of the MAC address. Bits [7:0] contain the last (6th) octet of the MAC address.
0x520 CTRL_CORE_MAC_ID_SW_3 ro — Standard Fuse keys, MAC ID_2 [31:0].
  [24:0] STD_FUSE_MAC_ID_SW_3 — This bit field contains the first three octets (the OUI) of the MAC address of the GMAC_SW port 1. Bits [23:16] contain the first octet of the MAC address. Bits [15:8] contain the second octet of the MAC address. Bits [7:0] contain the third octet of the MAC address.
0x534 CTRL_CORE_SMA_SW_1 — OCP Spare Register
  [26] RGMII2_ID_MODE_N rw — Ethernet RGMII port 2 internal delay on transmit(SR2.0) 0x0: Internal delay enabled 0x1: Internal delay disabled
  [25] RGMII1_ID_MODE_N rw — Ethernet RGMII port 1 internal delay on transmit(SR2.0) 0x0: Internal delay enabled 0x1: Internal delay disabled
  [24] DSS_CH2_ON_OFF rw — DSS Channel 2 Pixel clock control On/Off 0x0: HSYNC and VSYNC are driven on opposite edges of pixel clock than pixel data 0x1: HSYNC and VSYNC are driven according to bit DSS_CH2_RF
  [23] DSS_CH1_ON_OFF rw — DSS Channel 1 Pixel clock control On/Off 0x0: HSYNC and VSYNC are driven on opposite edges of pixel clock than pixel data 0x1: HSYNC and VSYNC are driven according to bit DSS_CH1_RF
  [22] DSS_CH0_ON_OFF rw — DSS Channel 0 Pixel clock control On/Off 0x0: HSYNC and VSYNC are driven on opposite edges of pixel clock than pixel data 0x1: HSYNC and VSYNC are driven according to bit DSS_CH0_RF
  [21] DSS_CH2_IPC rw — DSS Channel 2 IPC control 0x0: Data is driven on the LCD data lines on the rising edge of the pixel clock 0x1: Data is driven on the LCD data lines on the falling edge of the pixel clock
  [20] DSS_CH1_IPC rw — DSS Channel 1 IPC control 0x0: Data is driven on the LCD data lines on the rising edge of the pixel clock 0x1: Data is driven on the LCD data lines on the falling edge of the pixel clock
  [19] DSS_CH0_IPC rw — DSS Channel 0 IPC control 0x0: Data is driven on the LCD data lines on the rising edge of the pixel clock 0x1: Data is driven on the LCD data lines on the falling edge of the pixel clock
  [18] DSS_CH2_RF rw — DSS Channel 2 Rise/Fall control 0x0: HSYNC and VSYNC are driven on falling edge of pixel clock (if bit DSS_CH2_ON_OFF set to 1) 0x1: HSYNC and VSYNC are driven on rising edge of pixel clock (if bit DSS_CH2_ON_OFF set to 1)
  [17] DSS_CH1_RF rw — DSS Channel 1 Rise/Fall control 0x0: HSYNC and VSYNC are driven on falling edge of pixel clock (if bit DSS_CH1_ON_OFF set to 1) 0x1: HSYNC and VSYNC are driven on rising edge of pixel clock (if bit DSS_CH1_ON_OFF set to 1)
  [16] DSS_CH0_RF rw — DSS Channel 0 Rise/Fall control 0x0: HSYNC and VSYNC are driven on falling edge of pixel clock (if bit DSS_CH0_ON_OFF set to 1) 0x1: HSYNC and VSYNC are driven on rising edge of pixel clock (if bit DSS_CH0_ON_OFF set to 1)
  [10] VIP3_CLK_INV_PORT_1A rw — VIP3 Slice 1 Clock inversion for Port A enable 0x0: clock inversion is disabled 0x1: clock inversion is enabled
  [9] VIP3_CLK_INV_PORT_2A rw — VIP3 Slice 0 Clock inversion for Port A enable 0x0: clock inversion is disabled 0x1: clock inversion is enabled
  [8] VPE_CLK_DIV_BY_2_EN rw — Selects alternative clock source for VPE. 0x0: Default clock source from DPLL_CORE is selected 0x1: Alternative clock source from DPLL_VIDEO1 is selected
  [7] VIP2_CLK_INV_PORT_2B rw — VIP2 Slice 1 Clock inversion for Port B enable 0x0: clock inversion is disabled 0x1: clock inversion is enabled
  [6] VIP2_CLK_INV_PORT_1B rw — VIP2 Slice 0 Clock inversion for Port B enable 0x0: clock inversion is disabled 0x1: clock inversion is enabled
  [5] VIP2_CLK_INV_PORT_2A rw — VIP2 Slice 1 Clock inversion for Port A enable 0x0: clock inversion is disabled 0x1: clock inversion is enabled
  [4] VIP2_CLK_INV_PORT_1A rw — VIP2 Slice 0 Clock inversion for Port A enable 0x0: clock inversion is disabled 0x1: clock inversion is enabled
  [3] VIP1_CLK_INV_PORT_2B rw — VIP1 Slice 1 Clock inversion for Port B enable 0x0: clock inversion is disabled 0x1: clock inversion is enabled
  [2] VIP1_CLK_INV_PORT_1B rw — VIP1 Slice 0 Clock inversion for Port B enable 0x0: clock inversion is disabled 0x1: clock inversion is enabled
  [1] VIP1_CLK_INV_PORT_2A rw — VIP1 Slice 1 Clock inversion for Port A enable 0x0: clock inversion is disabled 0x1: clock inversion is enabled
  [0] VIP1_CLK_INV_PORT_1A rw — VIP1 Slice 0 Clock inversion for Port A enable 0x0: clock inversion is disabled 0x1: clock inversion is enabled
